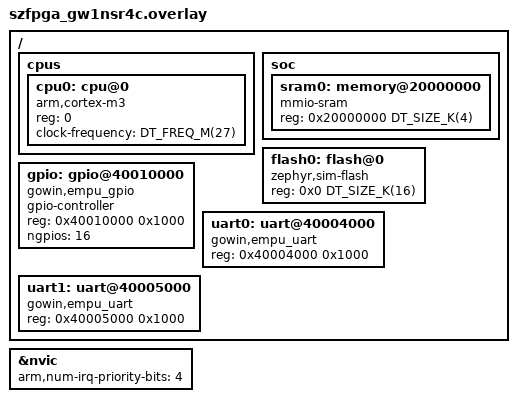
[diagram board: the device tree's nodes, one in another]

#include <freq.h>
#include <arm/armv7-m.dtsi>
#include <zephyr/dt-bindings/gpio/gpio.h>

#include <mem.h>

/ {
	#address-cells = <1>;
	#size-cells = <1>;
	cpus {
		#address-cells = <1>;
		#size-cells = <0>;

		cpu0: cpu@0 {
			compatible = "arm,cortex-m3";
			reg = <0>;
			#address-cells = <1>;
			#size-cells = <1>;
			clock-frequency = <DT_FREQ_M(27)>;
		};
	};

	soc {
		sram0: memory@20000000 {
			compatible = "mmio-sram";
		};
	};

	flash0: flash@0 {
		compatible = "zephyr,sim-flash";
	};

	gpio: gpio@40010000 {
		gpio-controller;
		compatible = "gowin,empu_gpio";
		reg = <0x40010000 0x1000>;
		ngpios = <16>;
		#gpio-cells = <2>;
	};

	uart0: uart@40004000 {
		compatible = "gowin,empu_uart";
		reg = <0x40004000 0x1000>;
	};

	uart1: uart@40005000 {
		compatible = "gowin,empu_uart";
		reg = <0x40005000 0x1000>;
	};
};

&nvic {
	arm,num-irq-priority-bits = <4>;
};

&flash0 {
	reg = <0x0 DT_SIZE_K(16)>;
};

&sram0 {
	reg = <0x20000000 DT_SIZE_K(4)>;
};

